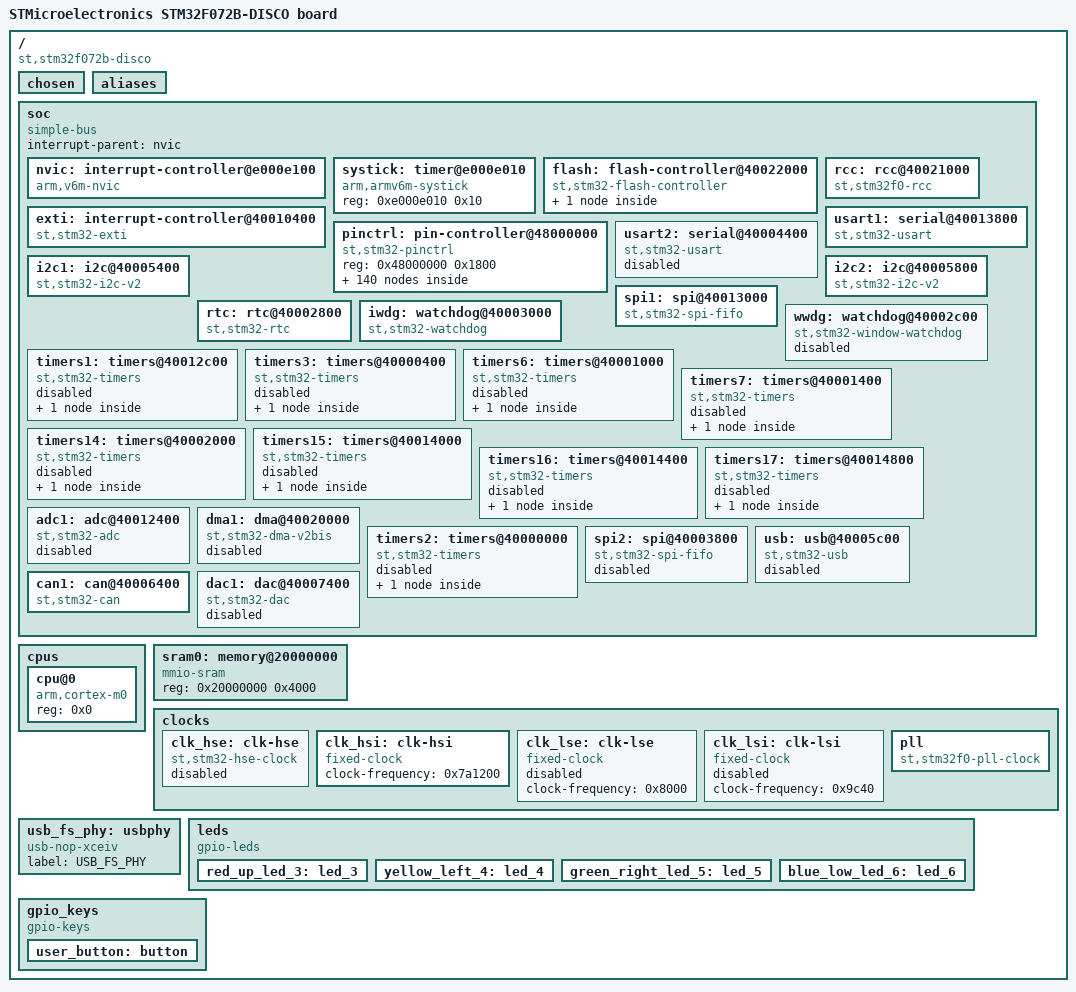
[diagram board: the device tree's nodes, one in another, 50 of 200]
/dts-v1/;

/ {
	#address-cells = < 0x1 >;
	#size-cells = < 0x1 >;
	model = "STMicroelectronics STM32F072B-DISCO board";
	compatible = "st,stm32f072b-disco";
	chosen {
		zephyr,flash-controller = &flash;
		zephyr,console = &usart1;
		zephyr,shell-uart = &usart1;
		zephyr,sram = &sram0;
		zephyr,flash = &flash0;
		zephyr,can-primary = &can1;
	};
	aliases {
		led0 = &red_up_led_3;
		led1 = &yellow_left_4;
		led2 = &green_right_led_5;
		led3 = &blue_low_led_6;
		sw0 = &user_button;
	};
	soc {
		#address-cells = < 0x1 >;
		#size-cells = < 0x1 >;
		compatible = "simple-bus";
		interrupt-parent = < &nvic >;
		ranges;
		nvic: interrupt-controller@e000e100 {
			#address-cells = < 0x1 >;
			compatible = "arm,v6m-nvic";
			reg = < 0xe000e100 0xc00 >;
			interrupt-controller;
			#interrupt-cells = < 0x2 >;
			arm,num-irq-priority-bits = < 0x2 >;
			phandle = < 0x1 >;
		};
		systick: timer@e000e010 {
			compatible = "arm,armv6m-systick";
			reg = < 0xe000e010 0x10 >;
		};
		flash: flash-controller@40022000 {
			compatible = "st,stm32-flash-controller", "st,stm32f0-flash-controller";
			label = "FLASH_CTRL";
			reg = < 0x40022000 0x400 >;
			interrupts = < 0x3 0x0 >;
			clocks = < &rcc 0x0 0x10 >;
			#address-cells = < 0x1 >;
			#size-cells = < 0x1 >;
			flash0: flash@8000000 {
				compatible = "st,stm32-nv-flash", "soc-nv-flash";
				label = "FLASH_STM32";
				write-block-size = < 0x2 >;
				max-erase-time = < 0x28 >;
				erase-block-size = < 0x800 >;
				reg = < 0x8000000 0x20000 >;
			};
		};
		rcc: rcc@40021000 {
			compatible = "st,stm32f0-rcc";
			#clock-cells = < 0x2 >;
			reg = < 0x40021000 0x400 >;
			clocks = < &pll >;
			clock-frequency = < 0x2dc6c00 >;
			ahb-prescaler = < 0x1 >;
			apb1-prescaler = < 0x1 >;
			phandle = < 0x2 >;
		};
		exti: interrupt-controller@40010400 {
			compatible = "st,stm32-exti";
			interrupt-controller;
			#interrupt-cells = < 0x1 >;
			reg = < 0x40010400 0x400 >;
		};
		pinctrl: pin-controller@48000000 {
			compatible = "st,stm32-pinctrl";
			#address-cells = < 0x1 >;
			#size-cells = < 0x1 >;
			reg = < 0x48000000 0x1800 >;
			gpioa: gpio@48000000 {
				compatible = "st,stm32-gpio";
				gpio-controller;
				#gpio-cells = < 0x2 >;
				reg = < 0x48000000 0x400 >;
				clocks = < &rcc 0x0 0x20000 >;
				label = "GPIOA";
				phandle = < 0x12 >;
			};
			gpiob: gpio@48000400 {
				compatible = "st,stm32-gpio";
				gpio-controller;
				#gpio-cells = < 0x2 >;
				reg = < 0x48000400 0x400 >;
				clocks = < &rcc 0x0 0x40000 >;
				label = "GPIOB";
			};
			gpioc: gpio@48000800 {
				compatible = "st,stm32-gpio";
				gpio-controller;
				#gpio-cells = < 0x2 >;
				reg = < 0x48000800 0x400 >;
				clocks = < &rcc 0x0 0x80000 >;
				label = "GPIOC";
				phandle = < 0x11 >;
			};
			gpiod: gpio@48000c00 {
				compatible = "st,stm32-gpio";
				gpio-controller;
				#gpio-cells = < 0x2 >;
				reg = < 0x48000c00 0x400 >;
				clocks = < &rcc 0x0 0x100000 >;
				label = "GPIOD";
			};
			gpiof: gpio@48001400 {
				compatible = "st,stm32-gpio";
				gpio-controller;
				#gpio-cells = < 0x2 >;
				reg = < 0x48001400 0x400 >;
				clocks = < &rcc 0x0 0x400000 >;
				label = "GPIOF";
			};
			gpioe: gpio@48001000 {
				compatible = "st,stm32-gpio";
				gpio-controller;
				#gpio-cells = < 0x2 >;
				reg = < 0x48001000 0x400 >;
				clocks = < &rcc 0x0 0x200000 >;
				label = "GPIOE";
			};
			adc_in0_pa0: adc_in0_pa0 {
				pinmux = < 0x10 >;
			};
			adc_in1_pa1: adc_in1_pa1 {
				pinmux = < 0x110 >;
			};
			adc_in2_pa2: adc_in2_pa2 {
				pinmux = < 0x210 >;
			};
			adc_in3_pa3: adc_in3_pa3 {
				pinmux = < 0x310 >;
			};
			adc_in4_pa4: adc_in4_pa4 {
				pinmux = < 0x410 >;
			};
			adc_in5_pa5: adc_in5_pa5 {
				pinmux = < 0x510 >;
			};
			adc_in6_pa6: adc_in6_pa6 {
				pinmux = < 0x610 >;
			};
			adc_in7_pa7: adc_in7_pa7 {
				pinmux = < 0x710 >;
			};
			adc_in8_pb0: adc_in8_pb0 {
				pinmux = < 0x1010 >;
			};
			adc_in9_pb1: adc_in9_pb1 {
				pinmux = < 0x1110 >;
			};
			adc_in10_pc0: adc_in10_pc0 {
				pinmux = < 0x2010 >;
			};
			adc_in11_pc1: adc_in11_pc1 {
				pinmux = < 0x2110 >;
			};
			adc_in12_pc2: adc_in12_pc2 {
				pinmux = < 0x2210 >;
			};
			adc_in13_pc3: adc_in13_pc3 {
				pinmux = < 0x2310 >;
			};
			adc_in14_pc4: adc_in14_pc4 {
				pinmux = < 0x2410 >;
			};
			adc_in15_pc5: adc_in15_pc5 {
				pinmux = < 0x2510 >;
			};
			can_rx_pa11: can_rx_pa11 {
				pinmux = < 0xb04 >;
				bias-pull-up;
			};
			can_rx_pb8: can_rx_pb8 {
				pinmux = < 0x1804 >;
				bias-pull-up;
				phandle = < 0xe >;
			};
			can_tx_pa12: can_tx_pa12 {
				pinmux = < 0xc04 >;
			};
			can_tx_pb9: can_tx_pb9 {
				pinmux = < 0x1904 >;
				phandle = < 0xf >;
			};
			dac_out1_pa4: dac_out1_pa4 {
				pinmux = < 0x410 >;
			};
			dac_out2_pa5: dac_out2_pa5 {
				pinmux = < 0x510 >;
			};
			i2c1_scl_pb6: i2c1_scl_pb6 {
				pinmux = < 0x1601 >;
				bias-pull-up;
				drive-open-drain;
			};
			i2c1_scl_pb8: i2c1_scl_pb8 {
				pinmux = < 0x1801 >;
				bias-pull-up;
				drive-open-drain;
				phandle = < 0x6 >;
			};
			i2c2_scl_pb10: i2c2_scl_pb10 {
				pinmux = < 0x1a01 >;
				bias-pull-up;
				drive-open-drain;
				phandle = < 0x8 >;
			};
			i2c2_scl_pb13: i2c2_scl_pb13 {
				pinmux = < 0x1d05 >;
				bias-pull-up;
				drive-open-drain;
			};
			i2c1_sda_pb7: i2c1_sda_pb7 {
				pinmux = < 0x1701 >;
				bias-pull-up;
				drive-open-drain;
			};
			i2c1_sda_pb9: i2c1_sda_pb9 {
				pinmux = < 0x1901 >;
				bias-pull-up;
				drive-open-drain;
				phandle = < 0x7 >;
			};
			i2c2_sda_pb11: i2c2_sda_pb11 {
				pinmux = < 0x1b01 >;
				bias-pull-up;
				drive-open-drain;
				phandle = < 0x9 >;
			};
			i2c2_sda_pb14: i2c2_sda_pb14 {
				pinmux = < 0x1e05 >;
				bias-pull-up;
				drive-open-drain;
			};
			i2s1_ck_pa5: i2s1_ck_pa5 {
				pinmux = < 0x500 >;
				slew-rate = "very-high-speed";
			};
			i2s1_ck_pb3: i2s1_ck_pb3 {
				pinmux = < 0x1300 >;
				slew-rate = "very-high-speed";
			};
			i2s2_ck_pb10: i2s2_ck_pb10 {
				pinmux = < 0x1a05 >;
				slew-rate = "very-high-speed";
			};
			i2s2_ck_pb13: i2s2_ck_pb13 {
				pinmux = < 0x1d00 >;
				slew-rate = "very-high-speed";
			};
			i2s1_sd_pa7: i2s1_sd_pa7 {
				pinmux = < 0x700 >;
			};
			i2s1_sd_pb5: i2s1_sd_pb5 {
				pinmux = < 0x1500 >;
			};
			i2s2_sd_pb15: i2s2_sd_pb15 {
				pinmux = < 0x1f00 >;
			};
			i2s2_sd_pc3: i2s2_sd_pc3 {
				pinmux = < 0x2301 >;
			};
			i2s1_ws_pa4: i2s1_ws_pa4 {
				pinmux = < 0x400 >;
			};
			i2s1_ws_pa15: i2s1_ws_pa15 {
				pinmux = < 0xf00 >;
			};
			i2s2_ws_pb9: i2s2_ws_pb9 {
				pinmux = < 0x1905 >;
			};
			i2s2_ws_pb12: i2s2_ws_pb12 {
				pinmux = < 0x1c00 >;
			};
			spi1_miso_pa6: spi1_miso_pa6 {
				pinmux = < 0x600 >;
				bias-pull-down;
			};
			spi1_miso_pb4: spi1_miso_pb4 {
				pinmux = < 0x1400 >;
				bias-pull-down;
				phandle = < 0xb >;
			};
			spi2_miso_pb14: spi2_miso_pb14 {
				pinmux = < 0x1e00 >;
				bias-pull-down;
			};
			spi2_miso_pc2: spi2_miso_pc2 {
				pinmux = < 0x2201 >;
				bias-pull-down;
			};
			spi1_mosi_pa7: spi1_mosi_pa7 {
				pinmux = < 0x700 >;
				bias-pull-down;
			};
			spi1_mosi_pb5: spi1_mosi_pb5 {
				pinmux = < 0x1500 >;
				bias-pull-down;
				phandle = < 0xc >;
			};
			spi2_mosi_pb15: spi2_mosi_pb15 {
				pinmux = < 0x1f00 >;
				bias-pull-down;
			};
			spi2_mosi_pc3: spi2_mosi_pc3 {
				pinmux = < 0x2301 >;
				bias-pull-down;
			};
			spi1_nss_pa4: spi1_nss_pa4 {
				pinmux = < 0x400 >;
				bias-pull-up;
			};
			spi1_nss_pa15: spi1_nss_pa15 {
				pinmux = < 0xf00 >;
				bias-pull-up;
			};
			spi2_nss_pb9: spi2_nss_pb9 {
				pinmux = < 0x1905 >;
				bias-pull-up;
			};
			spi2_nss_pb12: spi2_nss_pb12 {
				pinmux = < 0x1c00 >;
				bias-pull-up;
			};
			spi1_sck_pa5: spi1_sck_pa5 {
				pinmux = < 0x500 >;
				bias-pull-down;
				slew-rate = "very-high-speed";
			};
			spi1_sck_pb3: spi1_sck_pb3 {
				pinmux = < 0x1300 >;
				bias-pull-down;
				slew-rate = "very-high-speed";
				phandle = < 0xa >;
			};
			spi2_sck_pb10: spi2_sck_pb10 {
				pinmux = < 0x1a05 >;
				bias-pull-down;
				slew-rate = "very-high-speed";
			};
			spi2_sck_pb13: spi2_sck_pb13 {
				pinmux = < 0x1d00 >;
				bias-pull-down;
				slew-rate = "very-high-speed";
			};
			tim1_ch1n_pa7: tim1_ch1n_pa7 {
				pinmux = < 0x702 >;
			};
			tim1_ch1_pa8: tim1_ch1_pa8 {
				pinmux = < 0x802 >;
			};
			tim1_ch2_pa9: tim1_ch2_pa9 {
				pinmux = < 0x902 >;
			};
			tim1_ch3_pa10: tim1_ch3_pa10 {
				pinmux = < 0xa02 >;
			};
			tim1_ch4_pa11: tim1_ch4_pa11 {
				pinmux = < 0xb02 >;
			};
			tim1_ch2n_pb0: tim1_ch2n_pb0 {
				pinmux = < 0x1002 >;
			};
			tim1_ch3n_pb1: tim1_ch3n_pb1 {
				pinmux = < 0x1102 >;
			};
			tim1_ch1n_pb13: tim1_ch1n_pb13 {
				pinmux = < 0x1d02 >;
			};
			tim1_ch2n_pb14: tim1_ch2n_pb14 {
				pinmux = < 0x1e02 >;
			};
			tim1_ch3n_pb15: tim1_ch3n_pb15 {
				pinmux = < 0x1f02 >;
			};
			tim2_ch1_pa0: tim2_ch1_pa0 {
				pinmux = < 0x2 >;
			};
			tim2_ch2_pa1: tim2_ch2_pa1 {
				pinmux = < 0x102 >;
			};
			tim2_ch3_pa2: tim2_ch3_pa2 {
				pinmux = < 0x202 >;
			};
			tim2_ch4_pa3: tim2_ch4_pa3 {
				pinmux = < 0x302 >;
			};
			tim2_ch1_pa5: tim2_ch1_pa5 {
				pinmux = < 0x502 >;
			};
			tim2_ch1_pa15: tim2_ch1_pa15 {
				pinmux = < 0xf02 >;
			};
			tim2_ch2_pb3: tim2_ch2_pb3 {
				pinmux = < 0x1302 >;
			};
			tim2_ch3_pb10: tim2_ch3_pb10 {
				pinmux = < 0x1a02 >;
			};
			tim2_ch4_pb11: tim2_ch4_pb11 {
				pinmux = < 0x1b02 >;
			};
			tim3_ch1_pa6: tim3_ch1_pa6 {
				pinmux = < 0x601 >;
			};
			tim3_ch2_pa7: tim3_ch2_pa7 {
				pinmux = < 0x701 >;
			};
			tim3_ch3_pb0: tim3_ch3_pb0 {
				pinmux = < 0x1001 >;
			};
			tim3_ch4_pb1: tim3_ch4_pb1 {
				pinmux = < 0x1101 >;
			};
			tim3_ch1_pb4: tim3_ch1_pb4 {
				pinmux = < 0x1401 >;
			};
			tim3_ch2_pb5: tim3_ch2_pb5 {
				pinmux = < 0x1501 >;
			};
			tim3_ch1_pc6: tim3_ch1_pc6 {
				pinmux = < 0x2600 >;
			};
			tim3_ch2_pc7: tim3_ch2_pc7 {
				pinmux = < 0x2700 >;
			};
			tim3_ch3_pc8: tim3_ch3_pc8 {
				pinmux = < 0x2800 >;
			};
			tim3_ch4_pc9: tim3_ch4_pc9 {
				pinmux = < 0x2900 >;
			};
			tim14_ch1_pa4: tim14_ch1_pa4 {
				pinmux = < 0x404 >;
			};
			tim14_ch1_pa7: tim14_ch1_pa7 {
				pinmux = < 0x704 >;
			};
			tim14_ch1_pb1: tim14_ch1_pb1 {
				pinmux = < 0x1100 >;
			};
			tim15_ch1n_pa1: tim15_ch1n_pa1 {
				pinmux = < 0x105 >;
			};
			tim15_ch1_pa2: tim15_ch1_pa2 {
				pinmux = < 0x200 >;
			};
			tim15_ch2_pa3: tim15_ch2_pa3 {
				pinmux = < 0x300 >;
			};
			tim15_ch1_pb14: tim15_ch1_pb14 {
				pinmux = < 0x1e01 >;
			};
			tim15_ch1n_pb15: tim15_ch1n_pb15 {
				pinmux = < 0x1f03 >;
			};
			tim15_ch2_pb15: tim15_ch2_pb15 {
				pinmux = < 0x1f01 >;
			};
			tim16_ch1_pa6: tim16_ch1_pa6 {
				pinmux = < 0x605 >;
			};
			tim16_ch1n_pb6: tim16_ch1n_pb6 {
				pinmux = < 0x1602 >;
			};
			tim16_ch1_pb8: tim16_ch1_pb8 {
				pinmux = < 0x1802 >;
			};
			tim17_ch1_pa7: tim17_ch1_pa7 {
				pinmux = < 0x705 >;
			};
			tim17_ch1n_pb7: tim17_ch1n_pb7 {
				pinmux = < 0x1702 >;
			};
			tim17_ch1_pb9: tim17_ch1_pb9 {
				pinmux = < 0x1902 >;
			};
			usart1_cts_pa11: usart1_cts_pa11 {
				pinmux = < 0xb01 >;
				bias-pull-up;
				drive-open-drain;
			};
			usart2_cts_pa0: usart2_cts_pa0 {
				pinmux = < 0x1 >;
				bias-pull-up;
				drive-open-drain;
			};
			usart3_cts_pa6: usart3_cts_pa6 {
				pinmux = < 0x604 >;
				bias-pull-up;
				drive-open-drain;
			};
			usart3_cts_pb13: usart3_cts_pb13 {
				pinmux = < 0x1d04 >;
				bias-pull-up;
				drive-open-drain;
			};
			usart4_cts_pb7: usart4_cts_pb7 {
				pinmux = < 0x1704 >;
				bias-pull-up;
				drive-open-drain;
			};
			usart1_rts_pa12: usart1_rts_pa12 {
				pinmux = < 0xc01 >;
				bias-pull-up;
				drive-open-drain;
			};
			usart2_rts_pa1: usart2_rts_pa1 {
				pinmux = < 0x101 >;
				bias-pull-up;
				drive-open-drain;
			};
			usart3_rts_pb1: usart3_rts_pb1 {
				pinmux = < 0x1104 >;
				bias-pull-up;
				drive-open-drain;
			};
			usart3_rts_pb14: usart3_rts_pb14 {
				pinmux = < 0x1e04 >;
				bias-pull-up;
				drive-open-drain;
			};
			usart3_rts_pd2: usart3_rts_pd2 {
				pinmux = < 0x3201 >;
				bias-pull-up;
				drive-open-drain;
			};
			usart4_rts_pa15: usart4_rts_pa15 {
				pinmux = < 0xf04 >;
				bias-pull-up;
				drive-open-drain;
			};
			usart1_rx_pa10: usart1_rx_pa10 {
				pinmux = < 0xa01 >;
			};
			usart1_rx_pb7: usart1_rx_pb7 {
				pinmux = < 0x1700 >;
				phandle = < 0x5 >;
			};
			usart2_rx_pa3: usart2_rx_pa3 {
				pinmux = < 0x301 >;
			};
			usart2_rx_pa15: usart2_rx_pa15 {
				pinmux = < 0xf01 >;
			};
			usart3_rx_pb11: usart3_rx_pb11 {
				pinmux = < 0x1b04 >;
			};
			usart3_rx_pc5: usart3_rx_pc5 {
				pinmux = < 0x2501 >;
			};
			usart3_rx_pc11: usart3_rx_pc11 {
				pinmux = < 0x2b01 >;
			};
			usart4_rx_pa1: usart4_rx_pa1 {
				pinmux = < 0x104 >;
			};
			usart4_rx_pc11: usart4_rx_pc11 {
				pinmux = < 0x2b00 >;
			};
			usart1_tx_pa9: usart1_tx_pa9 {
				pinmux = < 0x901 >;
				bias-pull-up;
			};
			usart1_tx_pb6: usart1_tx_pb6 {
				pinmux = < 0x1600 >;
				bias-pull-up;
				phandle = < 0x4 >;
			};
			usart2_tx_pa2: usart2_tx_pa2 {
				pinmux = < 0x201 >;
				bias-pull-up;
			};
			usart2_tx_pa14: usart2_tx_pa14 {
				pinmux = < 0xe01 >;
				bias-pull-up;
			};
			usart3_tx_pb10: usart3_tx_pb10 {
				pinmux = < 0x1a04 >;
				bias-pull-up;
			};
			usart3_tx_pc4: usart3_tx_pc4 {
				pinmux = < 0x2401 >;
				bias-pull-up;
			};
			usart3_tx_pc10: usart3_tx_pc10 {
				pinmux = < 0x2a01 >;
				bias-pull-up;
			};
			usart4_tx_pa0: usart4_tx_pa0 {
				pinmux = < 0x4 >;
				bias-pull-up;
			};
			usart4_tx_pc10: usart4_tx_pc10 {
				pinmux = < 0x2a00 >;
				bias-pull-up;
			};
			usb_dm_pa11: usb_dm_pa11 {
				pinmux = < 0xb10 >;
			};
			usb_dp_pa12: usb_dp_pa12 {
				pinmux = < 0xc10 >;
			};
			usb_noe_pa13: usb_noe_pa13 {
				pinmux = < 0xd02 >;
			};
		};
		usart1: serial@40013800 {
			compatible = "st,stm32-usart", "st,stm32-uart";
			reg = < 0x40013800 0x400 >;
			clocks = < &rcc 0x4 0x4000 >;
			interrupts = < 0x1b 0x0 >;
			status = "okay";
			label = "UART_1";
			pinctrl-0 = < &usart1_tx_pb6 &usart1_rx_pb7 >;
			current-speed = < 0x1c200 >;
		};
		usart2: serial@40004400 {
			compatible = "st,stm32-usart", "st,stm32-uart";
			reg = < 0x40004400 0x400 >;
			clocks = < &rcc 0x2 0x20000 >;
			interrupts = < 0x1c 0x0 >;
			status = "disabled";
			label = "UART_2";
		};
		i2c1: i2c@40005400 {
			compatible = "st,stm32-i2c-v2";
			clock-frequency = < 0x61a80 >;
			#address-cells = < 0x1 >;
			#size-cells = < 0x0 >;
			reg = < 0x40005400 0x400 >;
			clocks = < &rcc 0x2 0x200000 >;
			interrupts = < 0x17 0x0 >;
			interrupt-names = "combined";
			status = "okay";
			label = "I2C_1";
			pinctrl-0 = < &i2c1_scl_pb8 &i2c1_sda_pb9 >;
		};
		i2c2: i2c@40005800 {
			compatible = "st,stm32-i2c-v2";
			clock-frequency = < 0x61a80 >;
			#address-cells = < 0x1 >;
			#size-cells = < 0x0 >;
			reg = < 0x40005800 0x400 >;
			clocks = < &rcc 0x2 0x400000 >;
			interrupts = < 0x18 0x0 >;
			interrupt-names = "combined";
			status = "okay";
			label = "I2C_2";
			pinctrl-0 = < &i2c2_scl_pb10 &i2c2_sda_pb11 >;
		};
		spi1: spi@40013000 {
			compatible = "st,stm32-spi-fifo", "st,stm32-spi";
			#address-cells = < 0x1 >;
			#size-cells = < 0x0 >;
			reg = < 0x40013000 0x400 >;
			clocks = < &rcc 0x4 0x1000 >;
			interrupts = < 0x19 0x3 >;
			status = "okay";
			label = "SPI_1";
			pinctrl-0 = < &spi1_sck_pb3 &spi1_miso_pb4 &spi1_mosi_pb5 >;
		};
		rtc: rtc@40002800 {
			compatible = "st,stm32-rtc";
			reg = < 0x40002800 0x400 >;
			clocks = < &rcc 0x2 0x10000000 >;
			interrupts = < 0x2 0x0 >;
			prescaler = < 0x8000 >;
			status = "okay";
			label = "RTC_0";
		};
		iwdg: watchdog@40003000 {
			compatible = "st,stm32-watchdog";
			reg = < 0x40003000 0x400 >;
			label = "IWDG";
			status = "okay";
		};
		wwdg: watchdog@40002c00 {
			compatible = "st,stm32-window-watchdog";
			reg = < 0x40002c00 0x400 >;
			clocks = < &rcc 0x2 0x800 >;
			label = "WWDG";
			interrupts = < 0x0 0x2 >;
			status = "disabled";
		};
		timers1: timers@40012c00 {
			compatible = "st,stm32-timers";
			reg = < 0x40012c00 0x400 >;
			clocks = < &rcc 0x4 0x800 >;
			interrupts = < 0xd 0x0 >, < 0xe 0x0 >;
			interrupt-names = "brk_up_trg_com", "cc";
			status = "disabled";
			label = "TIMERS_1";
			pwm {
				compatible = "st,stm32-pwm";
				status = "disabled";
				st,prescaler = < 0x0 >;
				label = "PWM_1";
				#pwm-cells = < 0x3 >;
			};
		};
		timers3: timers@40000400 {
			compatible = "st,stm32-timers";
			reg = < 0x40000400 0x400 >;
			clocks = < &rcc 0x2 0x2 >;
			interrupts = < 0x10 0x0 >;
			interrupt-names = "global";
			status = "disabled";
			label = "TIMERS_3";
			pwm {
				compatible = "st,stm32-pwm";
				status = "disabled";
				st,prescaler = < 0x0 >;
				label = "PWM_3";
				#pwm-cells = < 0x3 >;
			};
		};
		timers6: timers@40001000 {
			compatible = "st,stm32-timers";
			reg = < 0x40001000 0x400 >;
			clocks = < &rcc 0x2 0x10 >;
			interrupts = < 0x11 0x0 >;
			interrupt-names = "global";
			status = "disabled";
			label = "TIMERS_6";
			pwm {
				compatible = "st,stm32-pwm";
				status = "disabled";
				st,prescaler = < 0x0 >;
				label = "PWM_6";
				#pwm-cells = < 0x3 >;
			};
		};
		timers7: timers@40001400 {
			compatible = "st,stm32-timers";
			reg = < 0x40001400 0x400 >;
			clocks = < &rcc 0x2 0x20 >;
			interrupts = < 0x12 0x0 >;
			interrupt-names = "global";
			status = "disabled";
			label = "TIMERS_7";
			pwm {
				compatible = "st,stm32-pwm";
				status = "disabled";
				st,prescaler = < 0x0 >;
				label = "PWM_7";
				#pwm-cells = < 0x3 >;
			};
		};
		timers14: timers@40002000 {
			compatible = "st,stm32-timers";
			reg = < 0x40002000 0x400 >;
			clocks = < &rcc 0x2 0x100 >;
			interrupts = < 0x13 0x0 >;
			interrupt-names = "global";
			status = "disabled";
			label = "TIMERS_14";
			pwm {
				compatible = "st,stm32-pwm";
				status = "disabled";
				st,prescaler = < 0x0 >;
				label = "PWM_14";
				#pwm-cells = < 0x3 >;
			};
		};
		timers15: timers@40014000 {
			compatible = "st,stm32-timers";
			reg = < 0x40014000 0x400 >;
			clocks = < &rcc 0x4 0x10000 >;
			interrupts = < 0x14 0x0 >;
			interrupt-names = "global";
			status = "disabled";
			label = "TIMERS_15";
			pwm {
				compatible = "st,stm32-pwm";
				status = "disabled";
				st,prescaler = < 0x0 >;
				label = "PWM_15";
				#pwm-cells = < 0x3 >;
			};
		};
		timers16: timers@40014400 {
			compatible = "st,stm32-timers";
			reg = < 0x40014400 0x400 >;
			clocks = < &rcc 0x4 0x20000 >;
			interrupts = < 0x15 0x0 >;
			interrupt-names = "global";
			status = "disabled";
			label = "TIMERS_16";
			pwm {
				compatible = "st,stm32-pwm";
				status = "disabled";
				st,prescaler = < 0x0 >;
				label = "PWM_16";
				#pwm-cells = < 0x3 >;
			};
		};
		timers17: timers@40014800 {
			compatible = "st,stm32-timers";
			reg = < 0x40014800 0x400 >;
			clocks = < &rcc 0x4 0x40000 >;
			interrupts = < 0x16 0x0 >;
			interrupt-names = "global";
			status = "disabled";
			label = "TIMERS_17";
			pwm {
				compatible = "st,stm32-pwm";
				status = "disabled";
				st,prescaler = < 0x0 >;
				label = "PWM_17";
				#pwm-cells = < 0x3 >;
			};
		};
		adc1: adc@40012400 {
			compatible = "st,stm32-adc";
			reg = < 0x40012400 0x400 >;
			clocks = < &rcc 0x4 0x200 >;
			interrupts = < 0xc 0x0 >;
			status = "disabled";
			label = "ADC_1";
			#io-channel-cells = < 0x1 >;
		};
		dma1: dma@40020000 {
			compatible = "st,stm32-dma-v2bis";
			#dma-cells = < 0x2 >;
			reg = < 0x40020000 0x400 >;
			clocks = < &rcc 0x0 0x1 >;
			interrupts = < 0x9 0x0 0xa 0x0 0xa 0x0 0xb 0x0 0xb 0x0 0xb 0x0 0xb 0x0 >;
			status = "disabled";
			label = "DMA_1";
		};
		timers2: timers@40000000 {
			compatible = "st,stm32-timers";
			reg = < 0x40000000 0x400 >;
			clocks = < &rcc 0x2 0x1 >;
			interrupts = < 0xf 0x0 >;
			interrupt-names = "global";
			status = "disabled";
			label = "TIMERS_2";
			pwm {
				compatible = "st,stm32-pwm";
				status = "disabled";
				st,prescaler = < 0x0 >;
				label = "PWM_2";
				#pwm-cells = < 0x3 >;
			};
		};
		spi2: spi@40003800 {
			compatible = "st,stm32-spi-fifo", "st,stm32-spi";
			#address-cells = < 0x1 >;
			#size-cells = < 0x0 >;
			reg = < 0x40003800 0x400 >;
			clocks = < &rcc 0x2 0x4000 >;
			interrupts = < 0x1a 0x3 >;
			status = "disabled";
			label = "SPI_2";
		};
		usb: usb@40005c00 {
			compatible = "st,stm32-usb";
			reg = < 0x40005c00 0x400 >;
			interrupts = < 0x1f 0x0 >;
			interrupt-names = "usb";
			num-bidir-endpoints = < 0x8 >;
			ram-size = < 0x400 >;
			phys = < &usb_fs_phy >;
			clocks = < &rcc 0x2 0x800000 >;
			status = "disabled";
			label = "USB";
		};
		can1: can@40006400 {
			compatible = "st,stm32-can";
			#address-cells = < 0x1 >;
			#size-cells = < 0x0 >;
			reg = < 0x40006400 0x400 >;
			interrupts = < 0x1e 0x0 >;
			clocks = < &rcc 0x2 0x2000000 >;
			status = "okay";
			label = "CAN_1";
			bus-speed = < 0x1e848 >;
			sjw = < 0x1 >;
			prop-seg = < 0x0 >;
			phase-seg1 = < 0x5 >;
			phase-seg2 = < 0x6 >;
			pinctrl-0 = < &can_rx_pb8 &can_tx_pb9 >;
		};
		dac1: dac@40007400 {
			compatible = "st,stm32-dac";
			reg = < 0x40007400 0x400 >;
			clocks = < &rcc 0x2 0x20000000 >;
			status = "disabled";
			label = "DAC_1";
			#io-channel-cells = < 0x1 >;
		};
	};
	cpus {
		#address-cells = < 0x1 >;
		#size-cells = < 0x0 >;
		cpu@0 {
			device_type = "cpu";
			compatible = "arm,cortex-m0";
			reg = < 0x0 >;
		};
	};
	sram0: memory@20000000 {
		compatible = "mmio-sram";
		reg = < 0x20000000 0x4000 >;
	};
	clocks {
		clk_hse: clk-hse {
			#clock-cells = < 0x0 >;
			compatible = "st,stm32-hse-clock";
			status = "disabled";
		};
		clk_hsi: clk-hsi {
			#clock-cells = < 0x0 >;
			compatible = "fixed-clock";
			clock-frequency = < 0x7a1200 >;
			status = "okay";
			phandle = < 0x10 >;
		};
		clk_lse: clk-lse {
			#clock-cells = < 0x0 >;
			compatible = "fixed-clock";
			clock-frequency = < 0x8000 >;
			status = "disabled";
		};
		clk_lsi: clk-lsi {
			#clock-cells = < 0x0 >;
			compatible = "fixed-clock";
			clock-frequency = < 0x9c40 >;
			status = "disabled";
		};
		pll: pll {
			#clock-cells = < 0x0 >;
			compatible = "st,stm32f0-pll-clock";
			status = "okay";
			prediv = < 0x1 >;
			mul = < 0x6 >;
			clocks = < &clk_hsi >;
			phandle = < 0x3 >;
		};
	};
	usb_fs_phy: usbphy {
		compatible = "usb-nop-xceiv";
		#phy-cells = < 0x0 >;
		label = "USB_FS_PHY";
		phandle = < 0xd >;
	};
	leds {
		compatible = "gpio-leds";
		red_up_led_3: led_3 {
			gpios = < &gpioc 0x6 0x0 >;
			label = "User LD3";
		};
		yellow_left_4: led_4 {
			gpios = < &gpioc 0x8 0x0 >;
			label = "User LD4";
		};
		green_right_led_5: led_5 {
			gpios = < &gpioc 0x9 0x0 >;
			label = "User LD5";
		};
		blue_low_led_6: led_6 {
			gpios = < &gpioc 0x7 0x0 >;
			label = "User LD6";
		};
	};
	gpio_keys {
		compatible = "gpio-keys";
		user_button: button {
			label = "User";
			gpios = < &gpioa 0x0 0x1 >;
		};
	};
};
